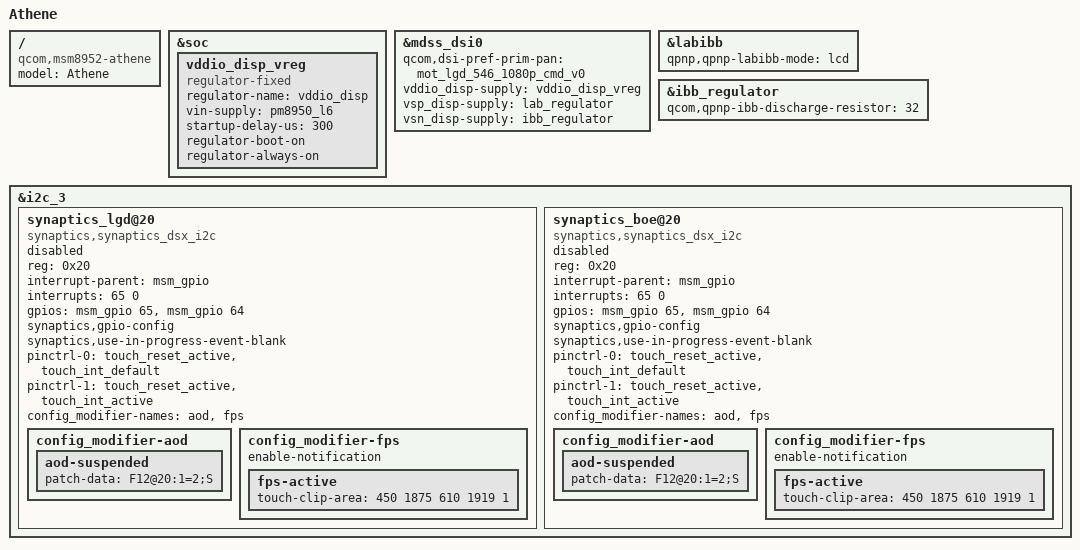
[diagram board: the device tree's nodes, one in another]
/* Copyright (c) 2015, Motorola Mobility Inc. All rights reserved.
 *
 * This program is free software; you can redistribute it and/or modify
 * it under the terms of the GNU General Public License version 2 and
 * only version 2 as published by the Free Software Foundation.
 *
 * This program is distributed in the hope that it will be useful,
 * but WITHOUT ANY WARRANTY; without even the implied warranty of
 * MERCHANTABILITY or FITNESS FOR A PARTICULAR PURPOSE.  See the
 * GNU General Public License for more details.
 */


#include "msm8952-moto-common.dtsi"
#include "msm8952-moto-dtv.dtsi"
#include "dsi-panel-mot-lgd-546-1080p-cmd.dtsi"
#include "dsi-panel-mot-boe-546-1080p-cmd.dtsi"

/ {
	model = "Athene";
	compatible = "qcom,msm8952-athene", "qcom,msm8952-moto",
			"qcom,msm8952";
};

&soc {
	vddio_disp_vreg: vddio_disp_vreg {
		compatible = "regulator-fixed";
		regulator-name = "vddio_disp";
		vin-supply = <&pm8950_l6>;
		startup-delay-us = <300>;
		regulator-boot-on;
		regulator-always-on;
	};
};

&mdss_dsi0 {
	qcom,dsi-pref-prim-pan = <&mot_lgd_546_1080p_cmd_v0>;
	vddio_disp-supply = <&vddio_disp_vreg>;
	vsp_disp-supply = <&lab_regulator>;
	vsn_disp-supply = <&ibb_regulator>;
};

/* display boost and inverting boost regulators */
&labibb {
	status = "ok";
	qpnp,qpnp-labibb-mode = "lcd";
};

&ibb_regulator {
	qcom,qpnp-ibb-discharge-resistor = <32>;
};

&i2c_3 { /* BLSP1 QUP3 */
	/delete-node/ synaptics@20;

	synaptics_lgd@20 {
		status = "/chosen", "mmi,panel_name", "mipi_mot_cmd_lgd_1080p_546";
		compatible = "synaptics,synaptics_dsx_i2c";
		reg = <0x20>;
		interrupt-parent = <&msm_gpio>;
		interrupts = <65 0>;
		gpios = <&msm_gpio 65 0>, /* IRQ */
			<&msm_gpio 64 0>; /* RESET */
		synaptics,gpio-config;
		synaptics,use-in-progress-event-blank;
		/* pins used by touchscreen */
		pinctrl-names = "default", "active";
		pinctrl-0 = <&touch_reset_active &touch_int_default>;
		pinctrl-1 = <&touch_reset_active &touch_int_active>;
		config_modifier-names = "aod", "fps";
		config_modifier-aod {
			aod-suspended {
				patch-data = "F12@20:1=2;S"; /* Set LPWG bit; Power->sleep */
			};
		};
		config_modifier-fps {
			enable-notification;
			fps-active {
				touch-clip-area = <450 1875 610 1919 1>;
			};
		};
	};

	synaptics_boe@20 {
		status = "/chosen", "mmi,panel_name", "mipi_mot_cmd_boe_1080p_546";
		compatible = "synaptics,synaptics_dsx_i2c";
		reg = <0x20>;
		interrupt-parent = <&msm_gpio>;
		interrupts = <65 0>;
		gpios = <&msm_gpio 65 0>, /* IRQ */
			<&msm_gpio 64 0>; /* RESET */
		synaptics,gpio-config;
		synaptics,use-in-progress-event-blank;
		/* pins used by touchscreen */
		pinctrl-names = "default", "active";
		pinctrl-0 = <&touch_reset_active &touch_int_default>;
		pinctrl-1 = <&touch_reset_active &touch_int_active>;
		config_modifier-names = "aod", "fps";
		config_modifier-aod {
			aod-suspended {
				patch-data = "F12@20:1=2;S"; /* Set LPWG bit; Power->sleep */
			};
		};
		config_modifier-fps {
			enable-notification;
			fps-active {
				touch-clip-area = <450 1875 610 1919 1>;
			};
		};
	};
};
